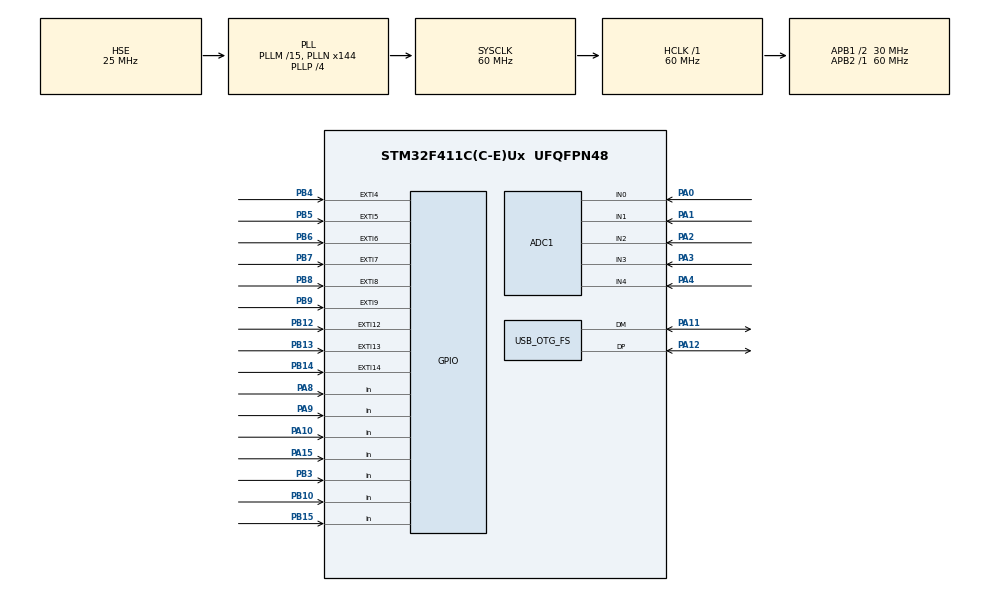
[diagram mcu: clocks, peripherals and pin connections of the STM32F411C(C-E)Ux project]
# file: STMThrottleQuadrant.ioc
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ADC1.Channel-5\#ChannelRegularConversion=ADC_CHANNEL_1
ADC1.ClockPrescaler=ADC_CLOCK_SYNC_PCLK_DIV2
ADC1.ContinuousConvMode=ENABLE
ADC1.DMAContinuousRequests=ENABLE
ADC1.NbrOfConversionFlag=1
ADC1.Rank-5\#ChannelRegularConversion=1
ADC1.SamplingTime-5\#ChannelRegularConversion=ADC_SAMPLETIME_3CYCLES
ADC1.master=1
Dma.ADC1.0.Direction=DMA_PERIPH_TO_MEMORY
Dma.ADC1.0.FIFOMode=DMA_FIFOMODE_DISABLE
Dma.ADC1.0.Instance=DMA2_Stream0
Dma.ADC1.0.MemDataAlignment=DMA_MDATAALIGN_HALFWORD
Dma.ADC1.0.MemInc=DMA_MINC_ENABLE
Dma.ADC1.0.Mode=DMA_CIRCULAR
Dma.ADC1.0.PeriphDataAlignment=DMA_PDATAALIGN_HALFWORD
Dma.ADC1.0.PeriphInc=DMA_PINC_DISABLE
Dma.ADC1.0.Priority=DMA_PRIORITY_LOW
Dma.Request0=ADC1
Mcu.Family=STM32F4
Mcu.Name=STM32F411C(C-E)Ux
Mcu.Package=UFQFPN48
NVIC.DMA2_Stream0_IRQn=true\:0\:0\:false\:false\:true\:false\:true\:true
NVIC.EXTI15_10_IRQn=true\:0\:0\:false\:false\:true\:true\:true\:true
NVIC.EXTI4_IRQn=true\:0\:0\:false\:false\:true\:true\:true\:true
NVIC.EXTI9_5_IRQn=true\:0\:0\:false\:false\:true\:true\:true\:true
NVIC.OTG_FS_IRQn=true\:0\:0\:false\:false\:true\:true\:true\:true
NVIC.PriorityGroup=NVIC_PRIORITYGROUP_4
PA0-WKUP.Signal=ADCx_IN0
PA1.Signal=ADCx_IN1
PA10.GPIO_PuPd=GPIO_PULLUP
PA10.Signal=GPIO_Input
PA11.Mode=Device_Only
PA11.Signal=USB_OTG_FS_DM
PA12.Mode=Device_Only
PA12.Signal=USB_OTG_FS_DP
PA15.GPIO_Mode=GPIO_MODE_INPUT
PA15.GPIO_PuPd=GPIO_PULLUP
PA15.Signal=GPIO_Input
PA2.Signal=ADCx_IN2
PA3.Signal=ADCx_IN3
PA4.Signal=ADCx_IN4
PA8.GPIO_Mode=GPIO_MODE_INPUT
PA8.GPIO_PuPd=GPIO_PULLUP
PA8.Signal=GPIO_Input
PA9.GPIO_Mode=GPIO_MODE_INPUT
PA9.GPIO_PuPd=GPIO_PULLUP
PA9.Signal=GPIO_Input
PB10.GPIO_PuPd=GPIO_PULLUP
PB10.Signal=GPIO_Input
PB12.GPIO_ModeDefaultEXTI=GPIO_MODE_IT_RISING_FALLING
PB12.GPIO_PuPd=GPIO_PULLUP
PB12.Signal=GPXTI12
PB13.GPIO_ModeDefaultEXTI=GPIO_MODE_IT_RISING_FALLING
PB13.GPIO_PuPd=GPIO_PULLUP
PB13.Signal=GPXTI13
PB14.Signal=GPXTI14
PB15.GPIO_Mode=GPIO_MODE_INPUT
PB15.GPIO_PuPd=GPIO_PULLUP
PB15.Signal=GPIO_Input
PB3.GPIO_Mode=GPIO_MODE_INPUT
PB3.GPIO_PuPd=GPIO_PULLUP
PB3.Signal=GPIO_Input
PB4.GPIO_ModeDefaultEXTI=GPIO_MODE_IT_RISING_FALLING
PB4.GPIO_PuPd=GPIO_PULLUP
PB4.Signal=GPXTI4
PB5.GPIO_ModeDefaultEXTI=GPIO_MODE_IT_RISING_FALLING
PB5.GPIO_PuPd=GPIO_PULLUP
PB5.Signal=GPXTI5
PB6.GPIO_ModeDefaultEXTI=GPIO_MODE_IT_RISING_FALLING
PB6.GPIO_PuPd=GPIO_PULLUP
PB6.Signal=GPXTI6
PB7.GPIO_ModeDefaultEXTI=GPIO_MODE_IT_RISING_FALLING
PB7.GPIO_PuPd=GPIO_PULLUP
PB7.Signal=GPXTI7
PB8.GPIO_ModeDefaultEXTI=GPIO_MODE_IT_RISING_FALLING
PB8.GPIO_PuPd=GPIO_PULLUP
PB8.Signal=GPXTI8
PB9.GPIO_ModeDefaultEXTI=GPIO_MODE_IT_RISING_FALLING
PB9.GPIO_PuPd=GPIO_PULLUP
PB9.Signal=GPXTI9
PH0\ -\ OSC_IN.Mode=HSE-External-Oscillator
PH0\ -\ OSC_IN.Signal=RCC_OSC_IN
PH1\ -\ OSC_OUT.Mode=HSE-External-Oscillator
PH1\ -\ OSC_OUT.Signal=RCC_OSC_OUT
ProjectManager.HeapSize=0x200
ProjectManager.StackSize=0x400
ProjectManager.TargetToolchain=STM32CubeIDE
RCC.48MHZClocksFreq_Value=48000000
RCC.AHBFreq_Value=60000000
RCC.APB1CLKDivider=RCC_HCLK_DIV2
RCC.APB1Freq_Value=30000000
RCC.APB1TimFreq_Value=60000000
RCC.APB2Freq_Value=60000000
RCC.APB2TimFreq_Value=60000000
RCC.CortexFreq_Value=60000000
RCC.HCLKFreq_Value=60000000
RCC.HSE_VALUE=25000000
RCC.HSI_VALUE=16000000
RCC.LSE_VALUE=32768
RCC.PLLM=15
RCC.PLLN=144
RCC.PLLP=RCC_PLLP_DIV4
RCC.PLLQ=5
RCC.SYSCLKFreq_VALUE=60000000
RCC.SYSCLKSource=RCC_SYSCLKSOURCE_PLLCLK
RCC.VCOOutputFreq_Value=240000000
SH.ADCx_IN0.0=ADC1_IN0,IN0
SH.ADCx_IN1.0=ADC1_IN1,IN1
SH.ADCx_IN2.0=ADC1_IN2,IN2
SH.ADCx_IN3.0=ADC1_IN3,IN3
SH.ADCx_IN4.0=ADC1_IN4,IN4
USB_DEVICE.CLASS_NAME_FS=CUSTOM_HID
USB_DEVICE.CUSTOM_HID_FS_BINTERVAL=0x1
USB_DEVICE.MANUFACTURER_STRING=Sharl0tka Aviation
USB_DEVICE.PRODUCT_STRING_CUSTOMHID_FS=Sharl0tka Aviation Throttle(R)
USB_DEVICE.USBD_CUSTOMHID_OUTREPORT_BUF_SIZE=64
USB_DEVICE.USBD_CUSTOM_HID_REPORT_DESC_SIZE=53
USB_DEVICE.VirtualMode=CustomHid
USB_DEVICE.VirtualModeFS=Custom_Hid_FS
USB_OTG_FS.VirtualMode=Device_Only
VP_USB_DEVICE_VS_USB_DEVICE_CUSTOM_HID_FS.Mode=CUSTOM_HID_FS
board=custom

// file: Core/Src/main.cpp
/* USER CODE BEGIN Header */
/**
  ******************************************************************************
  * @file           : main.c
  * @brief          : Main program body
  ******************************************************************************
  * @attention
  *
  * Copyright (c) 2024 STMicroelectronics.
  * All rights reserved.
  *
  * This software is licensed under terms that can be found in the LICENSE file
  * in the root directory of this software component.
  * If no LICENSE file comes with this software, it is provided AS-IS.
  *
  ******************************************************************************
  */
/* USER CODE END Header */
#include "main.h"
#include "usb_device.h"

 ADC_HandleTypeDef hadc1;
DMA_HandleTypeDef hdma_adc1;

void SystemClock_Config(void);
static void MX_GPIO_Init(void);
static void MX_ADC1_Init(void);
static void MX_DMA_Init(void);

/* USER CODE BEGIN 0 */
#include "yoba/yoba.h"
/* USER CODE END 0 */

int main(void)
{

  /* MCU Configuration--------------------------------------------------------*/

  /* Reset of all peripherals, Initializes the Flash interface and the Systick. */
  HAL_Init();

  /* Configure the system clock */
  SystemClock_Config();

  /* Initialize all configured peripherals */
  MX_GPIO_Init();
  MX_ADC1_Init();
  MX_DMA_Init();
  MX_USB_DEVICE_Init();
  /* USER CODE BEGIN 2 */
  yobaMain();
  /* USER CODE END 2 */

  /* Infinite loop */
  while (1)
  {

  }
}

void SystemClock_Config(void)
{
  RCC_OscInitTypeDef RCC_OscInitStruct = {0};
  RCC_ClkInitTypeDef RCC_ClkInitStruct = {0};

  /** Configure the main internal regulator output voltage
  */
  __HAL_RCC_PWR_CLK_ENABLE();
  __HAL_PWR_VOLTAGESCALING_CONFIG(PWR_REGULATOR_VOLTAGE_SCALE1);

  /** Initializes the RCC Oscillators according to the specified parameters
  * in the RCC_OscInitTypeDef structure.
  */
  RCC_OscInitStruct.OscillatorType = RCC_OSCILLATORTYPE_HSE;
  RCC_OscInitStruct.HSEState = RCC_HSE_ON;
  RCC_OscInitStruct.PLL.PLLState = RCC_PLL_ON;
  RCC_OscInitStruct.PLL.PLLSource = RCC_PLLSOURCE_HSE;
  RCC_OscInitStruct.PLL.PLLM = 15;
  RCC_OscInitStruct.PLL.PLLN = 144;
  RCC_OscInitStruct.PLL.PLLP = RCC_PLLP_DIV4;
  RCC_OscInitStruct.PLL.PLLQ = 5;
  if (HAL_RCC_OscConfig(&RCC_OscInitStruct) != HAL_OK)
  {
    Error_Handler();
  }

  /** Initializes the CPU, AHB and APB buses clocks
  */
  RCC_ClkInitStruct.ClockType = RCC_CLOCKTYPE_HCLK|RCC_CLOCKTYPE_SYSCLK
                              |RCC_CLOCKTYPE_PCLK1|RCC_CLOCKTYPE_PCLK2;
  RCC_ClkInitStruct.SYSCLKSource = RCC_SYSCLKSOURCE_PLLCLK;
  RCC_ClkInitStruct.AHBCLKDivider = RCC_SYSCLK_DIV1;
  RCC_ClkInitStruct.APB1CLKDivider = RCC_HCLK_DIV2;
  RCC_ClkInitStruct.APB2CLKDivider = RCC_HCLK_DIV1;

  if (HAL_RCC_ClockConfig(&RCC_ClkInitStruct, FLASH_LATENCY_1) != HAL_OK)
  {
    Error_Handler();
  }
}

static void MX_ADC1_Init(void)
{

  ADC_ChannelConfTypeDef sConfig = {0};

  /** Configure the global features of the ADC (Clock, Resolution, Data Alignment and number of conversion)
  */
  hadc1.Instance = ADC1;
  hadc1.Init.ClockPrescaler = ADC_CLOCK_SYNC_PCLK_DIV2;
  hadc1.Init.Resolution = ADC_RESOLUTION_12B;
  hadc1.Init.ScanConvMode = DISABLE;
  hadc1.Init.ContinuousConvMode = ENABLE;
  hadc1.Init.DiscontinuousConvMode = DISABLE;
  hadc1.Init.ExternalTrigConvEdge = ADC_EXTERNALTRIGCONVEDGE_NONE;
  hadc1.Init.ExternalTrigConv = ADC_SOFTWARE_START;
  hadc1.Init.DataAlign = ADC_DATAALIGN_RIGHT;
  hadc1.Init.NbrOfConversion = 1;
  hadc1.Init.DMAContinuousRequests = ENABLE;
  hadc1.Init.EOCSelection = ADC_EOC_SINGLE_CONV;
  if (HAL_ADC_Init(&hadc1) != HAL_OK)
  {
    Error_Handler();
  }

  /** Configure for the selected ADC regular channel its corresponding rank in the sequencer and its sample time.
  */
  sConfig.Channel = ADC_CHANNEL_1;
  sConfig.Rank = 1;
  sConfig.SamplingTime = ADC_SAMPLETIME_3CYCLES;
  if (HAL_ADC_ConfigChannel(&hadc1, &sConfig) != HAL_OK)
  {
    Error_Handler();
  }

}

static void MX_DMA_Init(void)
{

  /* DMA controller clock enable */
  __HAL_RCC_DMA2_CLK_ENABLE();

  /* DMA interrupt init */
  /* DMA2_Stream0_IRQn interrupt configuration */
  HAL_NVIC_SetPriority(DMA2_Stream0_IRQn, 0, 0);
  HAL_NVIC_EnableIRQ(DMA2_Stream0_IRQn);

}

static void MX_GPIO_Init(void)
{
  GPIO_InitTypeDef GPIO_InitStruct = {0};

  /* GPIO Ports Clock Enable */
  __HAL_RCC_GPIOH_CLK_ENABLE();
  __HAL_RCC_GPIOA_CLK_ENABLE();
  __HAL_RCC_GPIOB_CLK_ENABLE();

  /*Configure GPIO pins : PB10 PB15 PB3 */
  GPIO_InitStruct.Pin = GPIO_PIN_10|GPIO_PIN_15|GPIO_PIN_3;
  GPIO_InitStruct.Mode = GPIO_MODE_INPUT;
  GPIO_InitStruct.Pull = GPIO_PULLUP;
  HAL_GPIO_Init(GPIOB, &GPIO_InitStruct);

  /*Configure GPIO pins : PB12 PB13 PB4 PB5
                           PB6 PB7 PB8 PB9 */
  GPIO_InitStruct.Pin = GPIO_PIN_12|GPIO_PIN_13|GPIO_PIN_4|GPIO_PIN_5
                          |GPIO_PIN_6|GPIO_PIN_7|GPIO_PIN_8|GPIO_PIN_9;
  GPIO_InitStruct.Mode = GPIO_MODE_IT_RISING_FALLING;
  GPIO_InitStruct.Pull = GPIO_PULLUP;
  HAL_GPIO_Init(GPIOB, &GPIO_InitStruct);

  /*Configure GPIO pin : PB14 */
  GPIO_InitStruct.Pin = GPIO_PIN_14;
  GPIO_InitStruct.Mode = GPIO_MODE_IT_RISING;
  GPIO_InitStruct.Pull = GPIO_NOPULL;
  HAL_GPIO_Init(GPIOB, &GPIO_InitStruct);

  /*Configure GPIO pins : PA8 PA9 PA10 PA15 */
  GPIO_InitStruct.Pin = GPIO_PIN_8|GPIO_PIN_9|GPIO_PIN_10|GPIO_PIN_15;
  GPIO_InitStruct.Mode = GPIO_MODE_INPUT;
  GPIO_InitStruct.Pull = GPIO_PULLUP;
  HAL_GPIO_Init(GPIOA, &GPIO_InitStruct);

  /* EXTI interrupt init*/
  HAL_NVIC_SetPriority(EXTI4_IRQn, 0, 0);
  HAL_NVIC_EnableIRQ(EXTI4_IRQn);

  HAL_NVIC_SetPriority(EXTI9_5_IRQn, 0, 0);
  HAL_NVIC_EnableIRQ(EXTI9_5_IRQn);

  HAL_NVIC_SetPriority(EXTI15_10_IRQn, 0, 0);
  HAL_NVIC_EnableIRQ(EXTI15_10_IRQn);

}

/* USER CODE BEGIN 4 */
void HAL_GPIO_EXTI_Callback(uint16_t pin) {
	yobaInterrupt(pin);
}
/* USER CODE END 4 */

void Error_Handler(void)
{
  __disable_irq();
  while (1)
  {
  }
}
